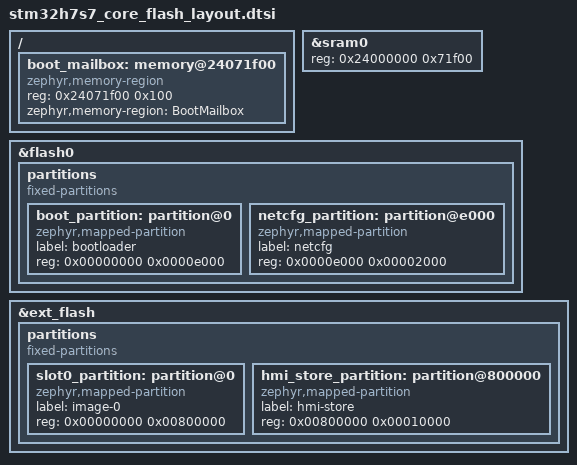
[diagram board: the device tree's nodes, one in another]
/*
 * SPDX-License-Identifier: Apache-2.0
 *
 * Flash layout shared by the network bootloader and every loader of this core (docs/network-bootloader.md and
 * variants/stm32h7s7_core_common/stm32h7rs_boot.h): the bootloader and the network settings sector fill the 64 KB
 * internal flash; the program slot and the HMI store live in external flash, the store right after the slot.
 * The RAM mailbox shared with the bootloader sits at the top of AXI SRAM, outside the program's RAM.
 */

/ {
	boot_mailbox: memory@24071f00 {
		compatible = "zephyr,memory-region", "mmio-sram";
		reg = <0x24071f00 0x100>;
		zephyr,memory-region = "BootMailbox";
		status = "okay";
	};
};

&sram0 {
	reg = <0x24000000 0x71f00>;
};

&flash0 {
	partitions {
		compatible = "fixed-partitions";
		#address-cells = <1>;
		#size-cells = <1>;
		ranges;

		boot_partition: partition@0 {
			compatible = "zephyr,mapped-partition";
			label = "bootloader";
			reg = <0x00000000 0x0000e000>;
		};

		netcfg_partition: partition@e000 {
			compatible = "zephyr,mapped-partition";
			label = "netcfg";
			reg = <0x0000e000 0x00002000>;
		};
	};
};

&ext_flash {
	partitions {
		compatible = "fixed-partitions";
		#address-cells = <1>;
		#size-cells = <1>;
		ranges;

		slot0_partition: partition@0 {
			compatible = "zephyr,mapped-partition";
			label = "image-0";
			reg = <0x00000000 0x00800000>;
		};

		hmi_store_partition: partition@800000 {
			compatible = "zephyr,mapped-partition";
			label = "hmi-store";
			reg = <0x00800000 0x00010000>;
		};
	};
};
